# bao1x register map
Vendor: baochip; File version: 1.0
Registers are 32-bit, read-write, reset 0x0 unless marked. A register's access mark holds for its fields unless they carry their own. Offsets are from the block's base; [hi:lo] are bit positions; {n}, {i} and the like mark numbered series.

## IRQARRAY17
Base 0xE000D000
0x00 EV_SOFT — Software interrupt trigger register. ) Bits set to `1` will trigger an interrupt. Interrupts trigger on write, but the value will persist in the register, allowing software to determine if a software interrupt was triggered by reading back the register. Software is responsible for clearing the register to 0. Repeated `1` writes without clearing will still trigger an interrupt.
  [15:0] trigger
0x04 EV_EDGE_TRIGGERED — If a bit is set to 1, then the hardware trigger is edge-triggered
  [15:0] use_edge
0x08 EV_POLARITY — If a bit is set to 1, then the polarity is rising edge triggered; 0 is falling edge triggered. Bit is ignored if `edge_triggered` is 0.
  [15:0] rising
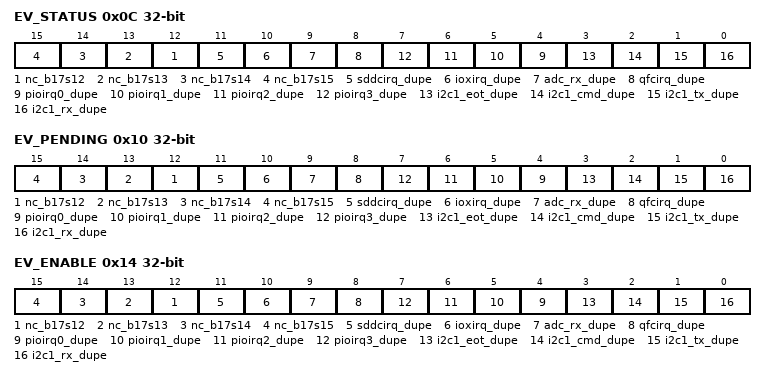
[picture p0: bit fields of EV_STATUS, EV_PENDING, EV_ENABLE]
0x0C EV_STATUS — `1` when a "nc_b17s15" event occurs. This event uses an `EventSourceFlex` form of triggering
  [n] nc_b17s{n} (n=12..15) — Level of the ``nc_b17s{n}`` event
  [11] sddcirq_dupe — Level of the ``sddcirq_dupe`` event
  [10] ioxirq_dupe — Level of the ``ioxirq_dupe`` event
  [9] adc_rx_dupe — Level of the ``adc_rx_dupe`` event
  [8] qfcirq_dupe — Level of the ``qfcirq_dupe`` event
  [n+4] pioirq{n}_dupe (n=0..3) — Level of the ``pioirq{n}_dupe`` event
  [3] i2c1_eot_dupe — Level of the ``i2c1_eot_dupe`` event
  [2] i2c1_cmd_dupe — Level of the ``i2c1_cmd_dupe`` event
  [1] i2c1_tx_dupe — Level of the ``i2c1_tx_dupe`` event
  [0] i2c1_rx_dupe — Level of the ``i2c1_rx_dupe`` event
0x10 EV_PENDING — `1` when a "nc_b17s15" event occurs. This event uses an `EventSourceFlex` form of triggering
  [n] nc_b17s{n} (n=12..15) — `1` when a "nc_b17s{n}" event occurs. This event uses an `EventSourceFlex` form of triggering
  [11] sddcirq_dupe — `1` when a "sddcirq_dupe" event occurs. This event uses an `EventSourceFlex` form of triggering
  [10] ioxirq_dupe — `1` when a "ioxirq_dupe" event occurs. This event uses an `EventSourceFlex` form of triggering
  [9] adc_rx_dupe — `1` when a "adc_rx_dupe" event occurs. This event uses an `EventSourceFlex` form of triggering
  [8] qfcirq_dupe — `1` when a "qfcirq_dupe" event occurs. This event uses an `EventSourceFlex` form of triggering
  [n+4] pioirq{n}_dupe (n=0..3) — `1` when a "pioirq{n}_dupe" event occurs. This event uses an `EventSourceFlex` form of triggering
  [3] i2c1_eot_dupe — `1` when a "i2c1_eot_dupe" event occurs. This event uses an `EventSourceFlex` form of triggering
  [2] i2c1_cmd_dupe — `1` when a "i2c1_cmd_dupe" event occurs. This event uses an `EventSourceFlex` form of triggering
  [1] i2c1_tx_dupe — `1` when a "i2c1_tx_dupe" event occurs. This event uses an `EventSourceFlex` form of triggering
  [0] i2c1_rx_dupe — `1` when a "i2c1_rx_dupe" event occurs. This event uses an `EventSourceFlex` form of triggering
0x14 EV_ENABLE — `1` when a "nc_b17s15" event occurs. This event uses an `EventSourceFlex` form of triggering
  [n] nc_b17s{n} (n=12..15) — Write a ``1`` to enable the ``nc_b17s{n}`` Event
  [11] sddcirq_dupe — Write a ``1`` to enable the ``sddcirq_dupe`` Event
  [10] ioxirq_dupe — Write a ``1`` to enable the ``ioxirq_dupe`` Event
  [9] adc_rx_dupe — Write a ``1`` to enable the ``adc_rx_dupe`` Event
  [8] qfcirq_dupe — Write a ``1`` to enable the ``qfcirq_dupe`` Event
  [n+4] pioirq{n}_dupe (n=0..3) — Write a ``1`` to enable the ``pioirq{n}_dupe`` Event
  [3] i2c1_eot_dupe — Write a ``1`` to enable the ``i2c1_eot_dupe`` Event
  [2] i2c1_cmd_dupe — Write a ``1`` to enable the ``i2c1_cmd_dupe`` Event
  [1] i2c1_tx_dupe — Write a ``1`` to enable the ``i2c1_tx_dupe`` Event
  [0] i2c1_rx_dupe — Write a ``1`` to enable the ``i2c1_rx_dupe`` Event

## MAILBOX
Base 0xE0018000
0x00 WDATA — Write data to outgoing FIFO.
0x04 RDATA — Read data from incoming FIFO.
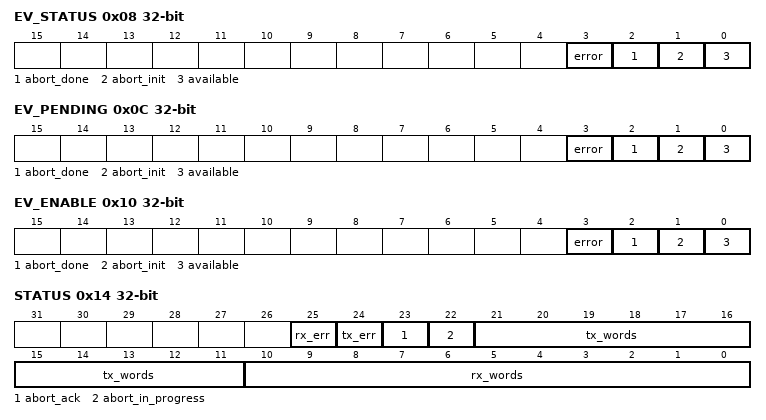
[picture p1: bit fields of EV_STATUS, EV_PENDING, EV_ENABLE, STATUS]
0x08 EV_STATUS — Triggers if either `tx_err` or `rx_err` are asserted
  [3] error — Level of the ``error`` event
  [2] abort_done — Level of the ``abort_done`` event
  [1] abort_init — Level of the ``abort_init`` event
  [0] available — Level of the ``available`` event
0x0C EV_PENDING — Triggers if either `tx_err` or `rx_err` are asserted
  [3] error — Triggers if either `tx_err` or `rx_err` are asserted
  [2] abort_done — Triggers when a previously initiated abort is acknowledged by peer
  [1] abort_init — Triggers when abort is asserted by the peer, and there is currently no abort in progress
  [0] available — Triggers when the `done` signal was asserted by the corresponding peer
0x10 EV_ENABLE — Triggers if either `tx_err` or `rx_err` are asserted
  [3] error — Write a ``1`` to enable the ``error`` Event
  [2] abort_done — Write a ``1`` to enable the ``abort_done`` Event
  [1] abort_init — Write a ``1`` to enable the ``abort_init`` Event
  [0] available — Write a ``1`` to enable the ``available`` Event
0x14 STATUS
  [25] rx_err — Set if read FIFO underflowed because we read too much data. Cleared on register read.
  [24] tx_err — Set if the write FIFO overflowed because we wrote too much data. Cleared on register read.
  [23] abort_ack — This bit is set by the peer that acknowledged the incoming abort (the later of the two, in case of an imperfect race condition). The abort response handler should check this bit; if it is set, no new acknowledgement shall be issued. The bit is cleared when an initiator initiates a new abort. The initiator shall also ignore the state of this bit if it is intending to initiate a new abort cycle.
  [22] abort_in_progress — This bit is set if an `aborting` event was initiated and is still in progress.
  [21:11] tx_words — Number of words pending in write FIFO. Free space is 1024 - `tx_avail`
  [10:0] rx_words — Number of words available to read
0x18 CONTROL
  [0] abort — Write `1` to this field to both initiate and acknowledge an abort. Empties both FIFOs, asserts `aborting`, and prevents an interrupt from being generated by an incoming abort request. New reads & writes are ignored until `aborted` is asserted from the peer.
0x1C DONE
  [0] done — Writing a `1` to this field indicates to the corresponding peer that a full packet is done loading. There is no need to clear this register after writing.
0x20 LOOPBACK
  [0] loopback — Writing a `1` to this field indicates that the mailbox should loopback to the local client. `0` connects it to the external core.
